# f28e12x_lfu_regs register map
Vendor: Texas Instruments
Peripheral module from a debugger description file (folder C2000).
Address unit: 16 bits
Registers are 32-bit, read-write, no defined reset value unless marked. A register's access mark holds for its fields unless they carry their own. Offsets are as the file gives them; lines under a group give offsets from that group; [hi:lo] are bit positions; {n}, {i} and the like mark numbered series; 'fields as' and 'values as' point back to an identical list; <NAME> marks a mode.

## LFU_REGS — LFU Registers
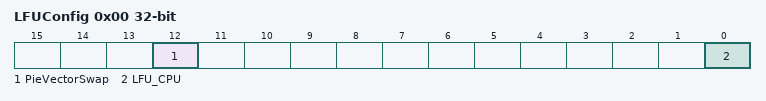
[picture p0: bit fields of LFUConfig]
0x00 LFUConfig — LFU configuration Register
  [12] PieVectorSwap — Swap of pie vector table
  [0] LFU_CPU — SW configuration to implement LFU
0x02 LFUStatus — LFU Configuration Status Register
  [12] PieVectorSwap — Indicate the status of PieVectorSwap
0x04 LFU_LOCK — LFU Lock Configuration
  [0] LFUConfig — Register lock configuration
0x06 LFU_COMMIT — LFU Commit Configuration
  [0] LFUConfig — Register commit configuration
